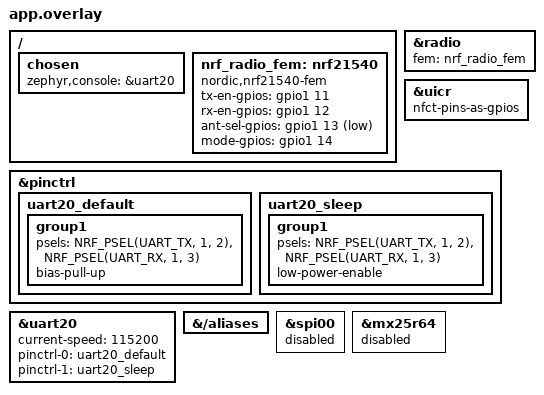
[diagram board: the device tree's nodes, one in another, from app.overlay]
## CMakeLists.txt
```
cmake_minimum_required(VERSION 3.20.0)
find_package(Zephyr REQUIRED HINTS $ENV{ZEPHYR_BASE})

project(nordic_wp_protocol)

target_sources(app PRIVATE src/main.c)
```

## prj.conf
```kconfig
CONFIG_GPIO=y

CONFIG_DEBUG_OPTIMIZATIONS=y

CONFIG_CLOCK_CONTROL=y
CONFIG_CLOCK_CONTROL_NRF=y
CONFIG_CLOCK_CONTROL_NRF_K32SRC_20PPM=y

CONFIG_ESB=y
CONFIG_ESB_CLOCK_INIT=y

# Factory device ID, used as the programmer's ID towards the tag.
CONFIG_HWINFO=y

CONFIG_PRINTK=y
CONFIG_CONSOLE=y

CONFIG_LOG=y
CONFIG_LOG_DEFAULT_LEVEL=3
CONFIG_LOG_MODE_IMMEDIATE=y

CONFIG_SERIAL=y
CONFIG_UART_INTERRUPT_DRIVEN=y
# Off by default on Nordic SoCs, needed to switch to the baud rate agreed with the PC.
CONFIG_UART_USE_RUNTIME_CONFIGURE=y
# Tag messages are streamed to the PC with fifo_fill, a larger buffer means fewer idle gaps between DMA transfers.
CONFIG_UART_20_NRF_TX_BUFFER_SIZE=256
CONFIG_UART_CONSOLE=n
CONFIG_LOG_BACKEND_UART=n

CONFIG_USE_SEGGER_RTT=y
CONFIG_RTT_CONSOLE=y
CONFIG_LOG_BACKEND_RTT=y

CONFIG_MAIN_STACK_SIZE=4096

# Must match the other device (dk_tag_emulator, NMini configs/prj_hw.conf), and fit PICOFIX_MAX_PACKET.
CONFIG_ESB_MAX_PAYLOAD_LENGTH=252
CONFIG_ESB_TX_FIFO_SIZE=2
CONFIG_ESB_RX_FIFO_SIZE=2
CONFIG_ESB_PIPE_COUNT=1
```

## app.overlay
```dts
#include <zephyr/dt-bindings/gpio/gpio.h>
#include <zephyr/dt-bindings/pinctrl/nrf-pinctrl.h>

// Make uart20 the Zephyr console.
/ {
	chosen {
		zephyr,console = &uart20;
	};

// Pin configuration of the FEM.
	nrf_radio_fem: nrf21540 {
		compatible = "nordic,nrf21540-fem";
		tx-en-gpios = <&gpio1 11 GPIO_ACTIVE_HIGH>;
		rx-en-gpios = <&gpio1 12 GPIO_ACTIVE_HIGH>;
		ant-sel-gpios = <&gpio1 13 GPIO_ACTIVE_LOW>; // Nordic configures signal as logically inactive, so changing polarity pulls it high.
		mode-gpios = <&gpio1 14 GPIO_ACTIVE_HIGH>;
		// PDN intentionally not listed here since it is connected on port 2, which is not supported by FEM integration (leaving blank should allow manual configuration).
	};
};

&radio {
	fem = <&nrf_radio_fem>;
};

&uicr {
	nfct-pins-as-gpios;
};

// UART pinctrl.
&pinctrl {
	/delete-node/ uart20_default;
	/delete-node/ uart20_sleep;

	uart20_default: uart20_default {
		group1 {
			psels = <NRF_PSEL(UART_TX, 1, 2)>,
				<NRF_PSEL(UART_RX, 1, 3)>;
			bias-pull-up;
		};
	};

	uart20_sleep: uart20_sleep {
		group1 {
			psels = <NRF_PSEL(UART_TX, 1, 2)>,
				<NRF_PSEL(UART_RX, 1, 3)>;
			low-power-enable;
		};
	};
};

&uart20 {
	status = "okay";
	current-speed = <115200>;

	pinctrl-0 = <&uart20_default>;
	pinctrl-1 = <&uart20_sleep>;
	pinctrl-names = "default", "sleep";
};

// Remove aliases that reference GPIO nodes which are about to be deleted.
&{/aliases} {
	/delete-property/ led3;
	/delete-property/ sw0;
	/delete-property/ mcuboot-button0;
};
/delete-node/ &button0; // P1.13 is Push Button 0 so needs erasing.
/delete-node/ &led3; // P1.14 is Green LED 3 so needs erasing.

// Disable spi00 since the corresponding pins are used in ESB.
&spi00 {
	status = "disabled";
};
// Child node of spi00 relating specifically to P2.00 - not needed but good to be explicit.
&mx25r64 {
	status = "disabled";
};
```

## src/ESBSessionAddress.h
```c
/*
 * ESBSessionAddress.h
 *
 * Copyright PathTrack Limited 2026
 *
 * Shared by the tag and the wireless programmer, the two copies must stay identical.
 */

#ifndef ESBSESSIONADDRESS_H_
#define ESBSESSIONADDRESS_H_

#include <stdint.h>

/* Pipe 0 base address used after PAIR_ACK, so other tag/programmer pairs on the channel neither receive nor ESB-ACK
 * this session's packets. Both sides know the tag's channel hopping seed and both IDs by then. The seed alone only
 * has 128 values, so the IDs make the address effectively unique per pair. The prefix stays as it is. */
static inline void ESBSession_baseAddress(const uint8_t pairingAddr[4], uint16_t seed, uint32_t baseID,
                                          uint32_t tagID, uint8_t addr[4]) {
    uint32_t hash = seed ^ (baseID * 0x9E3779B1u) ^ (tagID * 0x85EBCA77u);
    uint8_t matchesPairing = 1;

    /* MurmurHash3 finaliser, so similar IDs and seeds still give unrelated addresses */
    hash ^= hash >> 16;
    hash *= 0x85EBCA6Bu;
    hash ^= hash >> 13;
    hash *= 0xC2B2AE35u;
    hash ^= hash >> 16;

    for(uint8_t i = 0; i < 4; i++) {
        uint8_t byte = (uint8_t)(hash >> (8 * i));

        /* 0x55 and 0xAA look like the preamble, and 0x00 and 0xFF have too few level shifts, all of which Nordic
         * warn raise the packet error rate */
        if((byte == 0x00) || (byte == 0xFF) || (byte == 0x55) || (byte == 0xAA)) {
            byte ^= 0x0F;
        }
        addr[i] = byte;
        if(byte != pairingAddr[i]) {
            matchesPairing = 0;
        }
    }

    if(matchesPairing) {
        addr[0] ^= 0x0F;
    }
}

#endif /* ESBSESSIONADDRESS_H_ */
```

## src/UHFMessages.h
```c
/*
 * UHFMessages.h
 *
 * Created: 11/08/2026 14:34:50
 *  Author: Will
 */


#ifndef UHFMESSAGES_H_
#define UHFMESSAGES_H_

#include <stdint.h>

/* Pack all these struct/union defs to 1 byte as they have been explicitly aligned with nesting in mind */
#pragma pack(push, 1)

typedef struct ptTimePacked_t {
    uint8_t data[5];
} ptTimePacked_t;

/* ------------------------------------------ Tag <-> BS (32-bit) ----------------------------------------- */

/* Largest radio packet, header included, ESB's maximum payload. Must match the tag */
#define PICOFIX_MAX_PACKET  252

typedef struct picofix32UHFHeader_t {
    uint8_t u8picofixTag;
    uint8_t u8checkA;
    uint8_t u8checkB;
    uint8_t u8messageType;
    uint32_t u32senderID;
    uint32_t u32receiverID;
    uint16_t u16length;
} picofix32UHFHeader_t;

typedef struct picofix32UHF_dataToSend_t {
    uint16_t u16channelHoppingSeed;
    uint16_t u16numPages;
    ptTimePacked_t time;
    uint8_t u8batteryVoltage;
    uint8_t u8battType;
    int8_t i8RSSI; /* Special case: it's not part of the transmission and as such not returned in datLength */
} picofix32UHF_dataToSend_t;

typedef struct picofix32UHF_dataToOffload_t { /* Paired with BS version of picofix32UHF_dataToSend_t */
    uint16_t u16numPages;
    ptTimePacked_t time;
    uint8_t u8batteryVoltage;
    uint8_t u8battType;
    int8_t i8RSSI; /* Special case: it's not part of the transmission and as such not returned in datLength */
} picofix32UHF_dataToOffload_t;

typedef struct picofix32UHF_dataStop_t {
    int8_t i8tagRSSI;
} picofix32UHF_dataStop_t;

typedef struct picofix32UHF_dataTransfer_t {
    uint8_t u8data[512];
} picofix32UHF_dataTransfer_t;

typedef struct picofix32UHF_dataResponseContinue {
    uint8_t u8transferMode;
    uint8_t i8RSSI; /* Special case: We want access to this when calling DATA_STOP, however it's not part of the transmission and as such not returned in datLength */
} picofix32UHF_dataResponseContinue;

typedef struct picofix32UHF_pairInit_t {
    uint16_t u16channelHoppingSeed;
    uint8_t u8batteryVoltage;
} picofix32UHF_pairInit_t;

typedef struct  picofix32UHF_pairAck_t {
    uint8_t u8status;
    uint8_t u8padding;
    uint32_t u32maxBufferSize; /* Most pass-through bytes the base can take in one tag message */
} picofix32UHF_pairAck_t;

typedef union picofix32UHF_tagTXMessage_t {
    picofix32UHF_dataToSend_t dataToSend;
    picofix32UHF_dataToOffload_t dataToOffload;
    picofix32UHF_dataStop_t dataStop;
    picofix32UHF_dataTransfer_t dataTransfer;
    picofix32UHF_pairInit_t pairInit;
    uint8_t blob[PICOFIX_MAX_PACKET - sizeof(picofix32UHFHeader_t)];
} picofix32UHF_tagTXMessage_t;

typedef union picofix32UHF_tagRXMessage_t {
    picofix32UHF_dataResponseContinue dataResponseContinue;
    picofix32UHF_pairAck_t pairAck;
    uint8_t blob[PICOFIX_MAX_PACKET - sizeof(picofix32UHFHeader_t)];
} picofix32UHF_tagRXMessage_t;

typedef struct picofix32UHFTagTX_t {
    picofix32UHFHeader_t header;
    picofix32UHF_tagTXMessage_t message;
    uint8_t u8overflow[10];
} picofix32UHFTagTX_t;

typedef struct picofix32UHFTagRX_t {
    picofix32UHFHeader_t header;
    picofix32UHF_tagRXMessage_t message;
    uint8_t u8overflow[10];
} picofix32UHFTagRX_t;

#pragma pack(pop)

/* --------------------------------------- Common defines + enums -------------------------------------------- */

#define PICOFIX_32_MESSAGE_SIZE_DATA_TO_SEND				(sizeof(picofix32UHFHeader_t) + sizeof(picofix32UHF_dataToSend_t) - 1) /* Remove i8RSSI from the length since that isn't part of the transmission */
#define PICOFIX_32_MESSAGE_SIZE_DATA_STOP					(sizeof(picofix32UHFHeader_t) + sizeof(picofix32UHF_dataStop_t))
#define PICOFIX_32_MESSAGE_SIZE_DATA_TRANSFER				(sizeof(picofix32UHFHeader_t) + sizeof(picofix32UHF_dataTransfer_t))
#define PICOFIX_32_MESSAGE_SIZE_DATA_RESPONSE_CONTINUE		(sizeof(picofix32UHFHeader_t) + sizeof(picofix32UHF_dataResponseContinue) - 1) /* Remove u8tagRSSI from the length since that isn't part of the transmission */

/* Messages with no content */
#define PICOFIX_32_MESSAGE_SIZE_NOT_AUTHORISED				sizeof(picofix32UHFHeader_t)
#define PICOFIX_32_MESSAGE_SIZE_DATA_RESPONSE_FINAL			sizeof(picofix32UHFHeader_t)
#define PICOFIX_32_MESSAGE_SIZE_CONT_ACK					sizeof(picofix32UHFHeader_t)

#define PICOFIX_32_MESSAGE_SIZE_PAIR_INIT					(sizeof(picofix32UHFHeader_t) + sizeof(picofix32UHF_pairInit_t))
#define PICOFIX_32_MESSAGE_SIZE_CONFIG_ACK					(sizeof(picofix32UHFHeader_t) + sizeof(picofix32UHF_pairAck_t))
#define PICOFIX_32_MESSAGE_SIZE_DATA_TO_OFFLOAD				(sizeof(picofix32UHFHeader_t) + sizeof(picofix32UHF_dataToOffload_t) - 1) /* Remove i8RSSI from the length since that isn't part of the transmission */

#define PICOFIX_PCBIN_V3_MESSAGE_SIZE_CONNECT1				(sizeof(picofix32UHFHeader_t) + sizeof(picofixV3_passThroughHeader_t) + sizeof(picofixV3_connect1_t))
#define PICOFIX_PCBIN_V3_MESSAGE_SIZE_CONNECT2				(sizeof(picofix32UHFHeader_t) + sizeof(picofixV3_connect2_t))
#define PICOFIX_PCBIN_V3_MESSAGE_SIZE_CONNECT3				(sizeof(picofix32UHFHeader_t) + sizeof(picofixV3_passThroughHeader_t) + sizeof(picofixV3_connect3_t))
#define PICOFIX_PCBIN_V3_MESSAGE_SIZE_CONNECT4				(sizeof(picofix32UHFHeader_t) + sizeof(picofixV3_connect4_t))
#define PICOFIX_PCBIN_V3_MESSAGE_SIZE_CONNECT_ACK			(sizeof(picofix32UHFHeader_t) + sizeof(picofixV3_passThroughReceiveHeader_t) + sizeof(picofixV3_connectAck_t))

#define PICOFIX_PCBIN_V3_MESSAGE_SIZE_PING					(sizeof(picofix32UHFHeader_t) + sizeof(picofixV3_passThroughHeader_t) + sizeof(picofixV3_ping_t))
#define PICOFIX_PCBIN_V3_MESSAGE_SIZE_DISABLE_ACK			(sizeof(picofix32UHFHeader_t) + sizeof(picofixV3_passThroughHeader_t) + sizeof(picofixV3_disable_ack_t))
#define PICOFIX_PCBIN_V3_MESSAGE_SIZE_TIME_ACK				(sizeof(picofix32UHFHeader_t) + sizeof(picofixV3_passThroughHeader_t) + sizeof(picofixV3_time_ack_t))
#define PICOFIX_PCBIN_V3_MESSAGE_SIZE_CONFIG_ACK			(sizeof(picofix32UHFHeader_t) + sizeof(picofixV3_passThroughHeader_t) + sizeof(picofixV3_config_ack_t))

#define PICOFIX_PCBIN_V3_MESSAGE_SIZE_KEEPALIVE				(sizeof(picofix32UHFHeader_t) + sizeof(picofixV3_passThroughReceiveHeader_t) + sizeof(picofixV3_keepAlive_t))
#define PICOFIX_PCBIN_V3_MESSAGE_SIZE_DISABLE_REQUEST		(sizeof(picofix32UHFHeader_t) + sizeof(picofixV3_passThroughReceiveHeader_t) + sizeof(picofixV3_disableRequest_t))
#define PICOFIX_PCBIN_V3_MESSAGE_SIZE_TIME_UPDATE			(sizeof(picofix32UHFHeader_t) + sizeof(picofixV3_passThroughReceiveHeader_t) + sizeof(picofixV3_time_update_t))
#define PICOFIX_PCBIN_V3_MESSAGE_SIZE_CONFIG_UPDATE			(sizeof(picofix32UHFHeader_t) + sizeof(picofixV3_passThroughReceiveHeader_t) + sizeof(picofixV3_config_update_t))
#define PICOFIX_PCBIN_V3_MESSAGE_SIZE_RECONNECT				(sizeof(picofix32UHFHeader_t) + sizeof(picofixV3_passThroughReceiveHeader_t) + sizeof(picofixV3_reconnect_t))
#define PICOFIX_PCBIN_V3_MESSAGE_SIZE_POINTER_UPDATE		(sizeof(picofix32UHFHeader_t) + sizeof(picofixV3_passThroughReceiveHeader_t) + sizeof(picofixV3_pointer_update_t))

#define PICOFIX_8_MESSAGE_SIZE_CONFIG_REQUEST				(sizeof(picofix8UHFHeader_t) + sizeof(picofix8UHF_configRequest_t) - 1) /* Remove i8RSSI from the length since that isn't part of the transmission */
#define PICOFIX_8_MESSAGE_SIZE_CONFIG_REQUEST_V2			(sizeof(picofix8UHFHeader_t) + sizeof(picofix8UHF_configRequest_v2_t) - 1) /* Remove i8RSSI from the length since that isn't part of the transmission */
#define PICOFIX_8_MESSAGE_SIZE_CONFIG_DELIVERY_RESPONSE		(sizeof(picofix8UHFHeader_t) + sizeof(picofix8UHF_configDeliveryResponse_t))
#define PICOFIX_8_MESSAGE_SIZE_DATA_TO_SEND					(sizeof(picofix8UHFHeader_t) + sizeof(picofix8UHF_dataToSend_t) - 1) /* Remove i8RSSI from the length since that isn't part of the transmission */
#define PICOFIX_8_MESSAGE_SIZE_DATA_STOP					(sizeof(picofix8UHFHeader_t) + sizeof(picofix8UHF_dataStop_t))
#define PICOFIX_8_MESSAGE_SIZE_DATA_TRANSFER				(sizeof(picofix8UHFHeader_t) + sizeof(picofix8UHF_dataTransfer_t))
#define PICOFIX_8_MESSAGE_SIZE_CONFIG_DELIVERY				(sizeof(picofix8UHFHeader_t) + sizeof(picofix8UHF_configDelivery_t))
#define PICOFIX_8_MESSAGE_SIZE_PARAMETER_DELIVERY			(sizeof(picofix8UHFHeader_t) + sizeof(picofix8UHF_parameterDelivery_t))
#define PICOFIX_8_MESSAGE_SIZE_DATA_RESPONSE_CONTINUE		(sizeof(picofix8UHFHeader_t) + sizeof(picofix8UHF_dataResponseContinue))

/* Messages with no content */
#define PICOFIX_8_MESSAGE_SIZE_PARAMETER_DELIVERY_ACK		sizeof(picofix8UHFHeader_t)
#define PICOFIX_8_MESSAGE_SIZE_PARAMETER_DELIVERY_NACK		sizeof(picofix8UHFHeader_t)
#define PICOFIX_8_MESSAGE_SIZE_NOT_AUTHORISED				sizeof(picofix8UHFHeader_t)
#define PICOFIX_8_MESSAGE_SIZE_CONFIG_REQUEST_ACK			sizeof(picofix8UHFHeader_t)
#define PICOFIX_8_MESSAGE_SIZE_DATA_RESPONSE_FINAL			sizeof(picofix8UHFHeader_t)

#define UHF_PICOFIX_8_TAG		0x88
#define UHF_PICOFIX_8_BS		0xBB
#define UHF_PICOFIX_32_TAG		0x83
#define UHF_PICOFIX_32_BS		0xB3

enum {
    /* Tag -> BaseStation : Communication start */
    PICOFIX_CONFIG_REQUEST				= 0x01,
    PICOFIX_DATA_TO_SEND,
    PICOFIX_CONFIG_REQUEST_V2,
    /* Tag -> BaseStation : Config */
    PICOFIX_CONFIG_DELIVERY_RESPONSE	= 0x10,
    PICOFIX_PARAM_DELIVERY_ACK,
    PICOFIX_PARAM_DELIVERY_NACK,
    /* Tag -> BaseStation : Data */
    PICOFIX_NOT_AUTHORISED				= 0x20,
    PICOFIX_DATA_STOP,
    PICOFIX_DATA_TRANSFER,
    /* BaseStation -> Tag : Config */
    PICOFIX_CONFIG_REQUEST_ACK			= 0x80,
    PICOFIX_CONFIG_DELIVERY,
    PICOFIX_PARAM_DELIVERY,
    /* BaseStation -> Tag : Data */
    PICOFIX_DATA_ACK_CONTINUE			= 0x90,
    PICOFIX_DATA_ACK_FINAL,
    PICOFIX_DATA_NACK_CONTINUE,
    PICOFIX_DATA_NACK_FINAL,

    PICOFIX_V3_CONFIG_INIT				= 0xA0,
    PICOFIX_V3_CONFIG_ACK				= 0xA1,
    PICOFIX_V3_DATA_TO_OFFLOAD			= 0xA2,

    PICOFIX_V3_BASE_PASSTHROUGH			= 0xB0,
    PICOFIX_V3_BASE_PASSTHROUGH_CONT,
    PICOFIX_V3_BASE_CONT_ACK,

    PICOFIX_V3_TAG_PASSTHROUGH			= 0xC0,
    PICOFIX_V3_TAG_PASSTHROUGH_CONT,

    PICOFIX_V3_TAG_DISCONNECT			= 0xD0
};

enum {
    /* Tag -> BaseStation : Config */
    PICOFIX_PCBIN_V3_CONNECT1					= 0xA1,
    PICOFIX_PCBIN_V3_CONNECT2					= 0xA2,
    PICOFIX_PCBIN_V3_CONNECT3					= 0xA3,
    PICOFIX_PCBIN_V3_PING						= 0xA4,
    PICOFIX_PCBIN_V3_DISABLE_ACK				= 0xA5,
    PICOFIX_PCBIN_V3_TIME_ACK					= 0xA6,
    PICOFIX_PCBIN_V3_CONFIG_ACK					= 0xA7,
    PICOFIX_PCBIN_V3_CONNECT4					= 0xA8,
    PICOFIX_PCBIN_V3_CONNECT2_FAILED			= 0xAA,
    /* BaseStation -> Tag : Config */
    PICOFIX_PCBIN_V3_CONNECT_ACK				= 0xB3,
    PICOFIX_PCBIN_V3_KEEPALIVE					= 0xB4,
    PICOFIX_PCBIN_V3_DISABLE_REQUEST			= 0xB5,
    PICOFIX_PCBIN_V3_TIME_UPDATE				= 0xB6,
    PICOFIX_PCBIN_V3_CONFIG_UPDATE				= 0xB7,
    PICOFIX_PCBIN_V3_RECONNECT					= 0xB8,
    PICOFIX_PCBIN_V3_POINTER_UPDATE				= 0x8024,
    PICOFIX_PCBIN_V3_EEPROM_UPDATE				= 0x802F,
    PICOFIX_PCBIN_V3_OFFLOAD_DATA				= 0x8070
};

#endif /* UHFMESSAGES_H_ */
```

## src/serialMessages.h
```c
#include <stdint.h>

typedef struct serialPacketHeader_t{
    uint16_t u16header;
    uint16_t u16messageType;
    uint16_t u16length;
}serialPacketHeader_t;

/************************* Bridge -> PC ***************************/
#define SERIAL_TX_MAX_PAYLOAD 1024

/* Baud rate codes for the pair request and its ack, must match the host's SerialBaud */
#define SERIAL_BAUD_57600   0
#define SERIAL_BAUD_76800   1
#define SERIAL_BAUD_115200  2
#define SERIAL_BAUD_1M      3
#define SERIAL_BAUD_2M      4

#define SERIAL_TX_PAIR_REQUEST  0x0080
#define SERIAL_TX_PAIR_REQUEST_LEN 2
typedef struct serialPairRequest_t{
    serialPacketHeader_t header;
    uint8_t u8devType;
    uint8_t u8requestedBaud;
} serialPairRequest_t;

#define SERIAL_TX_FW_INFO  0x0081
#define SERIAL_TX_FW_INFO_LEN 6
typedef struct serialFWInfo_t{
    serialPacketHeader_t header;
    uint8_t u8protocolVer;
    uint8_t u8padding;
    uint32_t u32gitRev;
} serialFWInfo_t;

#define SERIAL_TX_KEEP_ALIVE  0x0084
#define SERIAL_TX_KEEP_ALIVE_LEN 0
typedef struct serialKeepAlive_t{
    serialPacketHeader_t header;
}serialKeepAlive_t;

/* Tells the PC its last message arrived corrupted, the PC then resends it */
#define SERIAL_TX_CRC_FAIL  0x00FE
#define SERIAL_TX_CRC_FAIL_LEN 0

/* Tag pass-through messages are already complete PC frames, so they are forwarded as they are. */

#define SERIAL_TX_HEADER 0x7470

typedef union serialTXMessage_t{
    serialPacketHeader_t header;
    serialPairRequest_t pairRequest;
    serialFWInfo_t fwInfo;
    serialKeepAlive_t keepAlive;
    uint8_t blob[SERIAL_TX_MAX_PAYLOAD + sizeof(serialPacketHeader_t) + 2 /* CRC */];
}serialTXMessage_t;

/************************* PC -> Bridge ***************************/

#define SERIAL_RX_MAX_PAYLOAD 1024

#define SERIAL_RX_PAIR_REQUEST_ACK 0x0080
typedef struct serialPairRequestAck_t{
    serialPacketHeader_t header;
    uint8_t u8acceptedBaud;
} serialPairRequestAck_t;

#define SERIAL_RX_FW_INFO_ACK 0x0003
typedef struct serialFWInfoAck_t{
    serialPacketHeader_t header;
    uint8_t u8status;
} serialFWInfoAck_t;

#define SERIAL_RX_KEEP_ALIVE_ACK 0x0084
typedef struct serialKeepAliveAck_t{
    serialPacketHeader_t header;
} serialKeepAliveAck_t;

/* Payload is sent to the tag. DISCONNECT's payload tells the tag to disconnect, ending the session. */
#define SERIAL_RX_PASS_THROUGH 0x00B0
#define SERIAL_RX_PASS_THROUGH_DISCONNECT 0x00D0
typedef struct serialPassThrough_t{
    serialPacketHeader_t header;
    uint8_t payload[SERIAL_RX_MAX_PAYLOAD];
} serialPassThrough_t;

#define SERIAL_RX_HEADER 0x6870

typedef union serialRXMessage_t{
    serialPacketHeader_t header;
    serialPairRequestAck_t pairRequestAck;
    serialFWInfoAck_t fwInfoAck;
    serialKeepAliveAck_t keepAliveAck;
    serialPassThrough_t passThrough;
    uint8_t blob[SERIAL_RX_MAX_PAYLOAD + sizeof(serialPacketHeader_t) + 2 /* CRC */];
}serialRXMessage_t;
```
